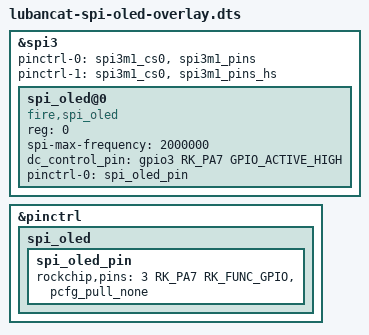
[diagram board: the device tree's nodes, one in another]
/dts-v1/;
/plugin/;

#include <dt-bindings/gpio/gpio.h>
#include <dt-bindings/pinctrl/rockchip.h>


/ {
    fragment@0 {
        target = <&spi3>;

        __overlay__ {
            status = "okay";
            #address-cells = <1>;
            #size-cells = <0>;
            pinctrl-names = "default", "high_speed";
            pinctrl-0 = <&spi3m1_cs0 &spi3m1_pins>;
            pinctrl-1 = <&spi3m1_cs0 &spi3m1_pins_hs>;

            spi_oled@0 {
                compatible = "fire,spi_oled";
                reg = <0>; //chip select 0:cs0  1:cs1
                spi-max-frequency = <2000000>; //spi output clock
                dc_control_pin = <&gpio3 RK_PA7 GPIO_ACTIVE_HIGH>;
                pinctrl-names = "default";
                pinctrl-0 = <&spi_oled_pin>;
            };
        };
    };

    fragment@1 {
        target = <&pinctrl>;

        __overlay__ {
            spi_oled {
                spi_oled_pin: spi_oled_pin {
                    rockchip,pins = <3 RK_PA7 RK_FUNC_GPIO &pcfg_pull_none>;
                };
            };
        };
    };
};
